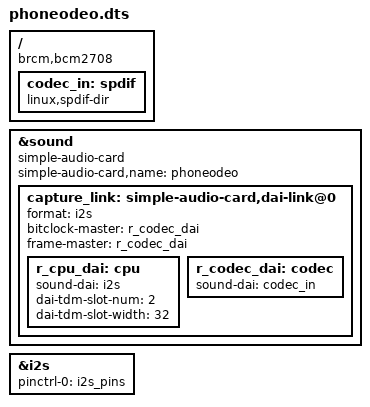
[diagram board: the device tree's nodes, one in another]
//Device tree overlay for generic stereo audio codec. ex) Asahi kasei AK4556
/dts-v1/;
/plugin/;

/ {
    compatible = "brcm,bcm2708";

    fragment@0 {
        target = <&sound>;
        __overlay__ {
            compatible = "simple-audio-card";
            simple-audio-card,name = "phoneodeo";
            status = "okay";

	    capture_link: simple-audio-card,dai-link@0 {
                format = "i2s";

                bitclock-master = <&r_codec_dai>;
                frame-master = <&r_codec_dai>;

                r_cpu_dai: cpu {
                    sound-dai = <&i2s>;

                    dai-tdm-slot-num = <2>;
                    dai-tdm-slot-width = <32>;
                };

                r_codec_dai: codec {
                    sound-dai = <&codec_in>;
                };
            };
        };
    };

    fragment@1 {
        target-path = "/";
        __overlay__ {
            codec_in: spdif {
                #address-cells = <0>;
                #size-cells = <0>;
                #sound-dai-cells = <0>;
                compatible = "linux,spdif-dir";
                status = "okay";
            };
        };
    };

    fragment@2 {
        target = <&i2s>;
        __overlay__ {
            #sound-dai-cells = <0>;
            pinctrl-0 = <&i2s_pins>;
            pinctrl-names = "default";
            status = "okay";
        };
    };
};
